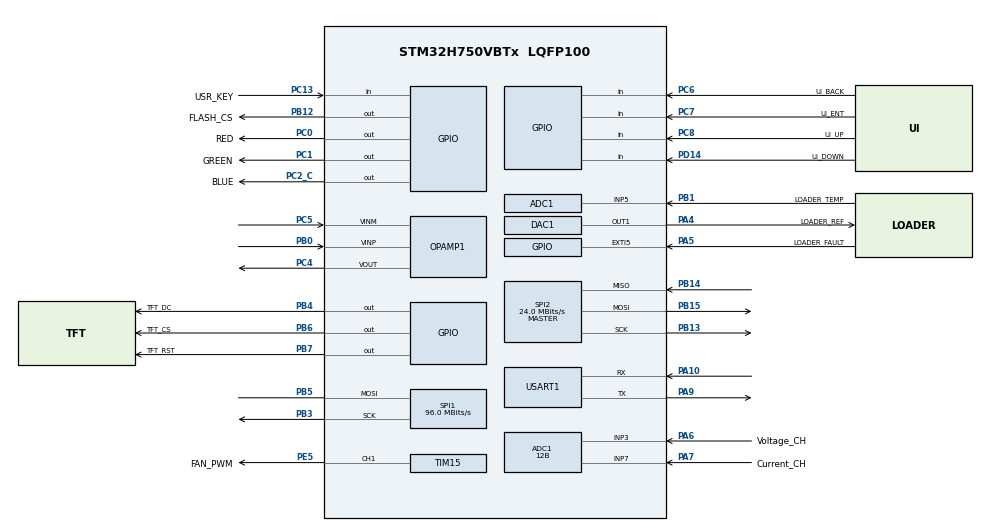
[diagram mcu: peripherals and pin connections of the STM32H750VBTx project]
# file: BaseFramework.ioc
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ADC1.Channel-3\#ChannelRegularConversion=ADC_CHANNEL_3
ADC1.Channel-4\#ChannelRegularConversion=ADC_CHANNEL_7
ADC1.Channel-5\#ChannelRegularConversion=ADC_CHANNEL_5
ADC1.ClockPrescaler=ADC_CLOCK_ASYNC_DIV4
ADC1.ContinuousConvMode=ENABLE
ADC1.ConversionDataManagement=ADC_CONVERSIONDATA_DMA_CIRCULAR
ADC1.ExternalTrigConv=ADC_SOFTWARE_START
ADC1.NbrOfConversion=3
ADC1.NbrOfConversionFlag=1
ADC1.OffsetNumber-3\#ChannelRegularConversion=ADC_OFFSET_NONE
ADC1.OffsetNumber-4\#ChannelRegularConversion=ADC_OFFSET_NONE
ADC1.OffsetNumber-5\#ChannelRegularConversion=ADC_OFFSET_NONE
ADC1.OffsetSignedSaturation-3\#ChannelRegularConversion=DISABLE
ADC1.Overrun=ADC_OVR_DATA_OVERWRITTEN
ADC1.Rank-3\#ChannelRegularConversion=1
ADC1.Rank-4\#ChannelRegularConversion=2
ADC1.Rank-5\#ChannelRegularConversion=3
ADC1.Resolution=ADC_RESOLUTION_12B
ADC1.SamplingTime-3\#ChannelRegularConversion=ADC_SAMPLETIME_64CYCLES_5
ADC1.SamplingTime-4\#ChannelRegularConversion=ADC_SAMPLETIME_64CYCLES_5
ADC1.SamplingTime-5\#ChannelRegularConversion=ADC_SAMPLETIME_387CYCLES_5
ADC1.master=1
ADC2.Channel-2\#ChannelRegularConversion=ADC_CHANNEL_4
ADC2.ClockPrescaler=ADC_CLOCK_ASYNC_DIV4
ADC2.ContinuousConvMode=ENABLE
ADC2.ConversionDataManagement=ADC_CONVERSIONDATA_DMA_CIRCULAR
ADC2.NbrOfConversionFlag=1
ADC2.OffsetNumber-2\#ChannelRegularConversion=ADC_OFFSET_NONE
ADC2.OffsetSignedSaturation-2\#ChannelRegularConversion=DISABLE
ADC2.Rank-2\#ChannelRegularConversion=1
ADC2.SamplingTime-2\#ChannelRegularConversion=ADC_SAMPLETIME_64CYCLES_5
CORTEX_M7.AccessPermission_S-Cortex_Memory_Protection_Unit_Region1_Settings_S=MPU_REGION_FULL_ACCESS
CORTEX_M7.AccessPermission_S-Cortex_Memory_Protection_Unit_Region2_Settings_S=MPU_REGION_FULL_ACCESS
CORTEX_M7.BaseAddress_S-Cortex_Memory_Protection_Unit_Region1_Settings_S=0x30000000
CORTEX_M7.BaseAddress_S-Cortex_Memory_Protection_Unit_Region2_Settings_S=0x90000000
CORTEX_M7.CPU_DCache=Enabled
CORTEX_M7.CPU_ICache=Enabled
CORTEX_M7.DisableExec_S-Cortex_Memory_Protection_Unit_Region1_Settings_S=MPU_INSTRUCTION_ACCESS_DISABLE
CORTEX_M7.Enable_S-Cortex_Memory_Protection_Unit_Region1_Settings_S=MPU_REGION_ENABLE
CORTEX_M7.Enable_S-Cortex_Memory_Protection_Unit_Region2_Settings_S=MPU_REGION_ENABLE
CORTEX_M7.IsBufferable_S-Cortex_Memory_Protection_Unit_Region2_Settings_S=MPU_ACCESS_BUFFERABLE
CORTEX_M7.IsCacheable_S-Cortex_Memory_Protection_Unit_Region2_Settings_S=MPU_ACCESS_CACHEABLE
CORTEX_M7.Size_S-Cortex_Memory_Protection_Unit_Region1_Settings_S=MPU_REGION_SIZE_64KB
CORTEX_M7.Size_S-Cortex_Memory_Protection_Unit_Region2_Settings_S=MPU_REGION_SIZE_8MB
CORTEX_M7.default_mode_Activation=1
DAC1.DAC1_OutputBuffer-DAC_OUT1=DAC_OUTPUTBUFFER_DISABLE
DAC1.DAC_Channel-DAC_OUT1=DAC_CHANNEL_1
DAC1.DAC_Trigger-DAC_OUT1=DAC_TRIGGER_SOFTWARE
DAC1.DAC_UserTrimming-DAC_OUT1=DAC_TRIMMING_FACTORY
Dma.ADC1.2.Direction=DMA_PERIPH_TO_MEMORY
Dma.ADC1.2.EventEnable=DISABLE
Dma.ADC1.2.FIFOMode=DMA_FIFOMODE_DISABLE
Dma.ADC1.2.Instance=DMA2_Stream0
Dma.ADC1.2.MemDataAlignment=DMA_MDATAALIGN_HALFWORD
Dma.ADC1.2.MemInc=DMA_MINC_ENABLE
Dma.ADC1.2.Mode=DMA_CIRCULAR
Dma.ADC1.2.PeriphDataAlignment=DMA_PDATAALIGN_HALFWORD
Dma.ADC1.2.PeriphInc=DMA_PINC_DISABLE
Dma.ADC1.2.Polarity=HAL_DMAMUX_REQ_GEN_RISING
Dma.ADC1.2.Priority=DMA_PRIORITY_MEDIUM
Dma.ADC1.2.RequestNumber=1
Dma.ADC1.2.SignalID=NONE
Dma.ADC1.2.SyncEnable=DISABLE
Dma.ADC1.2.SyncPolarity=HAL_DMAMUX_SYNC_NO_EVENT
Dma.ADC1.2.SyncRequestNumber=1
Dma.ADC1.2.SyncSignalID=NONE
Dma.ADC2.3.Direction=DMA_PERIPH_TO_MEMORY
Dma.ADC2.3.EventEnable=DISABLE
Dma.ADC2.3.FIFOMode=DMA_FIFOMODE_DISABLE
Dma.ADC2.3.Instance=DMA2_Stream1
Dma.ADC2.3.MemDataAlignment=DMA_MDATAALIGN_HALFWORD
Dma.ADC2.3.MemInc=DMA_MINC_ENABLE
Dma.ADC2.3.Mode=DMA_CIRCULAR
Dma.ADC2.3.PeriphDataAlignment=DMA_PDATAALIGN_HALFWORD
Dma.ADC2.3.PeriphInc=DMA_PINC_DISABLE
Dma.ADC2.3.Polarity=HAL_DMAMUX_REQ_GEN_RISING
Dma.ADC2.3.Priority=DMA_PRIORITY_MEDIUM
Dma.ADC2.3.RequestNumber=1
Dma.ADC2.3.SignalID=NONE
Dma.ADC2.3.SyncEnable=DISABLE
Dma.ADC2.3.SyncPolarity=HAL_DMAMUX_SYNC_NO_EVENT
Dma.ADC2.3.SyncRequestNumber=1
Dma.ADC2.3.SyncSignalID=NONE
Dma.Request0=USART1_RX
Dma.Request1=USART1_TX
Dma.Request2=ADC1
Dma.Request3=ADC2
Dma.Request4=SPI1_TX
Dma.SPI1_TX.4.Direction=DMA_MEMORY_TO_PERIPH
Dma.SPI1_TX.4.EventEnable=DISABLE
Dma.SPI1_TX.4.FIFOMode=DMA_FIFOMODE_ENABLE
Dma.SPI1_TX.4.FIFOThreshold=DMA_FIFO_THRESHOLD_FULL
Dma.SPI1_TX.4.Instance=DMA1_Stream2
Dma.SPI1_TX.4.MemBurst=DMA_MBURST_INC4
Dma.SPI1_TX.4.MemDataAlignment=DMA_MDATAALIGN_BYTE
Dma.SPI1_TX.4.MemInc=DMA_MINC_ENABLE
Dma.SPI1_TX.4.Mode=DMA_NORMAL
Dma.SPI1_TX.4.PeriphBurst=DMA_PBURST_SINGLE
Dma.SPI1_TX.4.PeriphDataAlignment=DMA_PDATAALIGN_BYTE
Dma.SPI1_TX.4.PeriphInc=DMA_PINC_DISABLE
Dma.SPI1_TX.4.Polarity=HAL_DMAMUX_REQ_GEN_RISING
Dma.SPI1_TX.4.Priority=DMA_PRIORITY_LOW
Dma.SPI1_TX.4.RequestNumber=1
Dma.SPI1_TX.4.SignalID=NONE
Dma.SPI1_TX.4.SyncEnable=DISABLE
Dma.SPI1_TX.4.SyncPolarity=HAL_DMAMUX_SYNC_NO_EVENT
Dma.SPI1_TX.4.SyncRequestNumber=1
Dma.SPI1_TX.4.SyncSignalID=NONE
Dma.USART1_RX.0.Direction=DMA_PERIPH_TO_MEMORY
Dma.USART1_RX.0.EventEnable=DISABLE
Dma.USART1_RX.0.FIFOMode=DMA_FIFOMODE_DISABLE
Dma.USART1_RX.0.Instance=DMA1_Stream1
Dma.USART1_RX.0.MemDataAlignment=DMA_MDATAALIGN_BYTE
Dma.USART1_RX.0.MemInc=DMA_MINC_ENABLE
Dma.USART1_RX.0.Mode=DMA_CIRCULAR
Dma.USART1_RX.0.PeriphDataAlignment=DMA_PDATAALIGN_BYTE
Dma.USART1_RX.0.PeriphInc=DMA_PINC_DISABLE
Dma.USART1_RX.0.Polarity=HAL_DMAMUX_REQ_GEN_RISING
Dma.USART1_RX.0.Priority=DMA_PRIORITY_LOW
Dma.USART1_RX.0.RequestNumber=1
Dma.USART1_RX.0.SignalID=NONE
Dma.USART1_RX.0.SyncEnable=DISABLE
Dma.USART1_RX.0.SyncPolarity=HAL_DMAMUX_SYNC_NO_EVENT
Dma.USART1_RX.0.SyncRequestNumber=1
Dma.USART1_RX.0.SyncSignalID=NONE
Dma.USART1_TX.1.Direction=DMA_MEMORY_TO_PERIPH
Dma.USART1_TX.1.EventEnable=DISABLE
Dma.USART1_TX.1.FIFOMode=DMA_FIFOMODE_DISABLE
Dma.USART1_TX.1.Instance=DMA1_Stream0
Dma.USART1_TX.1.MemDataAlignment=DMA_MDATAALIGN_BYTE
Dma.USART1_TX.1.MemInc=DMA_MINC_ENABLE
Dma.USART1_TX.1.Mode=DMA_NORMAL
Dma.USART1_TX.1.PeriphDataAlignment=DMA_PDATAALIGN_BYTE
Dma.USART1_TX.1.PeriphInc=DMA_PINC_DISABLE
Dma.USART1_TX.1.Polarity=HAL_DMAMUX_REQ_GEN_RISING
Dma.USART1_TX.1.Priority=DMA_PRIORITY_LOW
Dma.USART1_TX.1.RequestNumber=1
Dma.USART1_TX.1.SignalID=NONE
Dma.USART1_TX.1.SyncEnable=DISABLE
Dma.USART1_TX.1.SyncPolarity=HAL_DMAMUX_SYNC_NO_EVENT
Dma.USART1_TX.1.SyncRequestNumber=1
Dma.USART1_TX.1.SyncSignalID=NONE
FREERTOS.Tasks01=defaultTask,24,512,StartDefaultTask,Default,NULL,Dynamic,NULL,NULL
FREERTOS.configENABLE_FPU=1
FREERTOS.configTOTAL_HEAP_SIZE=65535
Mcu.Family=STM32H7
Mcu.Name=STM32H750VBTx
Mcu.Package=LQFP100
NVIC.DMA1_Stream0_IRQn=true\:5\:0\:false\:false\:true\:true\:false\:true\:true
NVIC.DMA1_Stream1_IRQn=true\:5\:0\:false\:false\:true\:true\:false\:true\:true
NVIC.DMA1_Stream2_IRQn=true\:5\:0\:false\:false\:true\:true\:false\:true\:true
NVIC.DMA2_Stream0_IRQn=true\:0\:0\:true\:false\:true\:false\:false\:true\:true
NVIC.DMA2_Stream1_IRQn=true\:5\:0\:false\:false\:true\:false\:false\:true\:true
NVIC.EXTI9_5_IRQn=true\:5\:0\:false\:false\:true\:true\:true\:true\:true
NVIC.PriorityGroup=NVIC_PRIORITYGROUP_4
NVIC.SPI1_IRQn=true\:5\:0\:false\:false\:true\:true\:false\:true\:true
NVIC.TIM16_IRQn=true\:5\:0\:false\:false\:true\:true\:true\:true\:true
NVIC.TIM17_IRQn=true\:15\:0\:false\:false\:true\:false\:false\:true\:true
NVIC.TimeBase=TIM17_IRQn
NVIC.TimeBaseIP=TIM17
NVIC.USART1_IRQn=true\:5\:0\:false\:false\:true\:true\:true\:true\:true
OPAMP1.PgaGain=OPAMP_PGA_GAIN_8_OR_MINUS_7
OPAMP1.SelfCalibration=Enable
OPAMP1.UserTrimming=OPAMP_TRIMMING_USER
PA10.Mode=Asynchronous
PA10.Signal=USART1_RX
PA13\ (JTMS/SWDIO).Mode=Serial_Wire
PA13\ (JTMS/SWDIO).Signal=DEBUG_JTMS-SWDIO
PA14\ (JTCK/SWCLK).Mode=Serial_Wire
PA14\ (JTCK/SWCLK).Signal=DEBUG_JTCK-SWCLK
PA4.GPIO_Label=LOADER_REF
PA4.Signal=COMP_DAC11_group
PA5.GPIO_Label=LOADER_FAULT
PA5.GPIO_PuPd=GPIO_PULLDOWN
PA5.Signal=GPXTI5
PA6.GPIO_Label=Voltage_CH
PA6.Signal=ADCx_INP3
PA7.GPIO_Label=Current_CH
PA7.Signal=ADCx_INP7
PA9.Mode=Asynchronous
PA9.Signal=USART1_TX
PB0.Mode=PGA Connected-INVERTINGINPUT_IO0
PB0.Signal=OPAMP1_VINP
PB1.GPIO_Label=LOADER_TEMP
PB1.Signal=ADCx_INP5
PB12.GPIO_Label=FLASH_CS
PB12.Signal=GPIO_Output
PB13.Mode=Full_Duplex_Master
PB13.Signal=SPI2_SCK
PB14.Mode=Full_Duplex_Master
PB14.Signal=SPI2_MISO
PB15.Mode=Full_Duplex_Master
PB15.Signal=SPI2_MOSI
PB3\ (JTDO/TRACESWO).Mode=Simplex_Bidirectional_Master
PB3\ (JTDO/TRACESWO).Signal=SPI1_SCK
PB4\ (NJTRST).GPIO_Label=TFT_DC
PB4\ (NJTRST).GPIO_Speed=GPIO_SPEED_FREQ_VERY_HIGH
PB4\ (NJTRST).Signal=GPIO_Output
PB5.Mode=Simplex_Bidirectional_Master
PB5.Signal=SPI1_MOSI
PB6.GPIO_FM6=SYSCFG_PMCR_I2C_PB6_FMP
PB6.GPIO_Label=TFT_CS
PB6.GPIO_Speed=GPIO_SPEED_FREQ_VERY_HIGH
PB6.Signal=GPIO_Output
PB7.GPIO_FM7=SYSCFG_PMCR_I2C_PB7_FMP
PB7.GPIO_Label=TFT_RST
PB7.GPIO_Speed=GPIO_SPEED_FREQ_VERY_HIGH
PB7.Signal=GPIO_Output
PC0.GPIO_Label=RED
PC0.Signal=GPIO_Output
PC1.GPIO_Label=GREEN
PC1.Signal=GPIO_Output
PC13.GPIO_Label=USR_KEY
PC13.GPIO_PuPd=GPIO_PULLUP
PC13.Signal=GPIO_Input
PC14-OSC32_IN\ (OSC32_IN).Mode=LSE-External-Oscillator
PC14-OSC32_IN\ (OSC32_IN).Signal=RCC_OSC32_IN
PC15-OSC32_OUT\ (OSC32_OUT).Mode=LSE-External-Oscillator
PC15-OSC32_OUT\ (OSC32_OUT).Signal=RCC_OSC32_OUT
PC2_C.GPIO_Label=BLUE
PC2_C.Signal=GPIO_Output
PC4.Signal=SharedAnalog_PC4
PC5.Mode=PGA Connected-INVERTINGINPUT_IO0
PC5.Signal=OPAMP1_VINM
PC6.GPIO_Label=UI_BACK
PC6.GPIO_PuPd=GPIO_PULLUP
PC6.Signal=GPIO_Input
PC7.GPIO_Label=UI_ENT
PC7.GPIO_PuPd=GPIO_PULLUP
PC7.Signal=GPIO_Input
PC8.GPIO_Label=UI_UP
PC8.GPIO_PuPd=GPIO_PULLUP
PC8.Signal=GPIO_Input
PD14.GPIO_Label=UI_DOWN
PD14.GPIO_PuPd=GPIO_PULLUP
PD14.Signal=GPIO_Input
PE5.GPIO_Label=FAN_PWM
PE5.Signal=S_TIM15_CH1
PH0-OSC_IN\ (PH0).Mode=HSE-External-Oscillator
PH0-OSC_IN\ (PH0).Signal=RCC_OSC_IN
PH1-OSC_OUT\ (PH1).Mode=HSE-External-Oscillator
PH1-OSC_OUT\ (PH1).Signal=RCC_OSC_OUT
ProjectManager.HeapSize=0x400
ProjectManager.StackSize=0x4000
ProjectManager.TargetToolchain=MDK-ARM V5.32
RCC.ADCFreq_Value=80000000
RCC.APB1Freq_Value=120000000
RCC.APB2Freq_Value=120000000
RCC.APB3Freq_Value=120000000
RCC.APB4Freq_Value=120000000
RCC.CortexFreq_Value=480000000
RCC.D1PPRE=RCC_APB3_DIV2
RCC.D2PPRE1=RCC_APB1_DIV2
RCC.D2PPRE2=RCC_APB2_DIV2
RCC.D3PPRE=RCC_APB4_DIV2
RCC.DIVM1=4
RCC.DIVM2=4
RCC.DIVN1=60
RCC.DIVN2=10
RCC.DIVQ1=5
RCC.HCLKFreq_Value=240000000
RCC.HPRE=RCC_HCLK_DIV2
RCC.PLL2FRACN=0
RCC.PLL3FRACN=0
RCC.PLLFRACN=0
RCC.SYSCLKFreq_VALUE=480000000
RCC.SYSCLKSource=RCC_SYSCLKSOURCE_PLLCLK
RCC.USBFreq_Value=192000000
SH.ADCx_INP3.0=ADC1_INP3,IN3-Single-Ended
SH.ADCx_INP5.0=ADC1_INP5,IN5-Single-Ended
SH.ADCx_INP7.0=ADC1_INP7,IN7-Single-Ended
SH.COMP_DAC11_group.0=DAC1_OUT1,DAC_OUT1
SH.S_TIM15_CH1.0=TIM15_CH1,PWM Generation1 CH1
SH.SharedAnalog_PC4.0=ADC2_INP4
SH.SharedAnalog_PC4.1=OPAMP1_VOUT,PGA Connected-INVERTINGINPUT_IO0
SPI1.BaudRatePrescaler=SPI_BAUDRATEPRESCALER_2
SPI1.CLKPhase=SPI_PHASE_1EDGE
SPI1.CLKPolarity=SPI_POLARITY_LOW
SPI1.CalculateBaudRate=96.0 MBits/s
SPI1.DataSize=SPI_DATASIZE_8BIT
SPI1.Direction=SPI_DIRECTION_1LINE
SPI1.FifoThreshold=SPI_FIFO_THRESHOLD_08DATA
SPI1.Mode=SPI_MODE_MASTER
SPI1.VirtualType=VM_MASTER
SPI2.BaudRatePrescaler=SPI_BAUDRATEPRESCALER_8
SPI2.CLKPhase=SPI_PHASE_2EDGE
SPI2.CLKPolarity=SPI_POLARITY_HIGH
SPI2.CalculateBaudRate=24.0 MBits/s
SPI2.DataSize=SPI_DATASIZE_8BIT
SPI2.Direction=SPI_DIRECTION_2LINES
SPI2.Mode=SPI_MODE_MASTER
SPI2.NSSPMode=SPI_NSS_PULSE_ENABLE
SPI2.VirtualType=VM_MASTER
STMicroelectronics.X-CUBE-ALGOBUILD.1.4.0.LibraryCcDSPOoLibraryJjDSPOoLibrary=true
TIM15.Channel-PWM\ Generation1\ CH1=TIM_CHANNEL_1
TIM15.Prescaler=240
TIM16.Period=3
TIM16.Prescaler=24000
USART1.FIFOMode=FIFOMODE_DISABLE
USART1.VirtualMode-Asynchronous=VM_ASYNC
VP_ADC2_OPAMP1_OUT.Mode=IN4-OPAMP1-Single-Ended
VP_FREERTOS_VS_CMSIS_V2.Mode=CMSIS_V2
VP_MEMORYMAP_VS_MEMORYMAP.Mode=CurAppReg
VP_STMicroelectronics.X-CUBE-ALGOBUILD_VS_DSPOoLibraryJjLibrary_1.4.0_1.4.0.Mode=DSPOoLibraryJjLibrary
VP_SYS_VS_tim17.Mode=TIM17
VP_TIM16_VS_ClockSourceINT.Mode=Enable_Timer
board=custom

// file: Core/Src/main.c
/* USER CODE BEGIN Header */
/**
  ******************************************************************************
  * @file           : main.c
  * @brief          : Main program body
  ******************************************************************************
  * @attention
  *
  * Copyright (c) 2026 STMicroelectronics.
  * All rights reserved.
  *
  * This software is licensed under terms that can be found in the LICENSE file
  * in the root directory of this software component.
  * If no LICENSE file comes with this software, it is provided AS-IS.
  *
  ******************************************************************************
  */
/* USER CODE END Header */
#include "main.h"
#include "cmsis_os.h"
#include "adc.h"
#include "dac.h"
#include "dma.h"
#include "opamp.h"
#include "spi.h"
#include "tim.h"
#include "usart.h"
#include "gpio.h"

/* USER CODE BEGIN Includes */
#include "bsp/board.h"
/* USER CODE END Includes */

void SystemClock_Config(void);
void PeriphCommonClock_Config(void);
static void MPU_Config(void);
void MX_FREERTOS_Init(void);

int main(void)
{

  /* MPU Configuration--------------------------------------------------------*/
  MPU_Config();

  /* Enable the CPU Cache */

  /* Enable I-Cache---------------------------------------------------------*/
  SCB_EnableICache();

  /* Enable D-Cache---------------------------------------------------------*/
  SCB_EnableDCache();

  /* MCU Configuration--------------------------------------------------------*/

  /* Reset of all peripherals, Initializes the Flash interface and the Systick. */
  HAL_Init();

  /* Configure the system clock */
  SystemClock_Config();

  /* Configure the peripherals common clocks */
  PeriphCommonClock_Config();

  /* Initialize all configured peripherals */
  MX_GPIO_Init();
  MX_DMA_Init();
  MX_USART1_UART_Init();
  MX_SPI2_Init();
  MX_SPI1_Init();
  MX_ADC1_Init();
  MX_TIM16_Init();
  MX_DAC1_Init();
  MX_ADC2_Init();
  MX_OPAMP1_Init();
  MX_TIM15_Init();
  /* USER CODE BEGIN 2 */
  board_early_init();
  /* USER CODE END 2 */

  /* Init scheduler */
  osKernelInitialize();  /* Call init function for freertos objects (in cmsis_os2.c) */
  MX_FREERTOS_Init();

  /* Start scheduler */
  osKernelStart();

  /* We should never get here as control is now taken by the scheduler */

  /* Infinite loop */
  while (1)
  {

  }
}

void SystemClock_Config(void)
{
  RCC_OscInitTypeDef RCC_OscInitStruct = {0};
  RCC_ClkInitTypeDef RCC_ClkInitStruct = {0};

  /** Supply configuration update enable
  */
  HAL_PWREx_ConfigSupply(PWR_LDO_SUPPLY);

  /** Configure the main internal regulator output voltage
  */
  __HAL_PWR_VOLTAGESCALING_CONFIG(PWR_REGULATOR_VOLTAGE_SCALE0);

  while(!__HAL_PWR_GET_FLAG(PWR_FLAG_VOSRDY)) {}

  /** Initializes the RCC Oscillators according to the specified parameters
  * in the RCC_OscInitTypeDef structure.
  */
  RCC_OscInitStruct.OscillatorType = RCC_OSCILLATORTYPE_HSI;
  RCC_OscInitStruct.HSIState = RCC_HSI_DIV1;
  RCC_OscInitStruct.HSICalibrationValue = RCC_HSICALIBRATION_DEFAULT;
  RCC_OscInitStruct.PLL.PLLState = RCC_PLL_ON;
  RCC_OscInitStruct.PLL.PLLSource = RCC_PLLSOURCE_HSI;
  RCC_OscInitStruct.PLL.PLLM = 4;
  RCC_OscInitStruct.PLL.PLLN = 60;
  RCC_OscInitStruct.PLL.PLLP = 2;
  RCC_OscInitStruct.PLL.PLLQ = 5;
  RCC_OscInitStruct.PLL.PLLR = 2;
  RCC_OscInitStruct.PLL.PLLRGE = RCC_PLL1VCIRANGE_3;
  RCC_OscInitStruct.PLL.PLLVCOSEL = RCC_PLL1VCOWIDE;
  RCC_OscInitStruct.PLL.PLLFRACN = 0;
  if (HAL_RCC_OscConfig(&RCC_OscInitStruct) != HAL_OK)
  {
    Error_Handler();
  }

  /** Initializes the CPU, AHB and APB buses clocks
  */
  RCC_ClkInitStruct.ClockType = RCC_CLOCKTYPE_HCLK|RCC_CLOCKTYPE_SYSCLK
                              |RCC_CLOCKTYPE_PCLK1|RCC_CLOCKTYPE_PCLK2
                              |RCC_CLOCKTYPE_D3PCLK1|RCC_CLOCKTYPE_D1PCLK1;
  RCC_ClkInitStruct.SYSCLKSource = RCC_SYSCLKSOURCE_PLLCLK;
  RCC_ClkInitStruct.SYSCLKDivider = RCC_SYSCLK_DIV1;
  RCC_ClkInitStruct.AHBCLKDivider = RCC_HCLK_DIV2;
  RCC_ClkInitStruct.APB3CLKDivider = RCC_APB3_DIV2;
  RCC_ClkInitStruct.APB1CLKDivider = RCC_APB1_DIV2;
  RCC_ClkInitStruct.APB2CLKDivider = RCC_APB2_DIV2;
  RCC_ClkInitStruct.APB4CLKDivider = RCC_APB4_DIV2;

  if (HAL_RCC_ClockConfig(&RCC_ClkInitStruct, FLASH_LATENCY_4) != HAL_OK)
  {
    Error_Handler();
  }
}

void PeriphCommonClock_Config(void)
{
  RCC_PeriphCLKInitTypeDef PeriphClkInitStruct = {0};

  /** Initializes the peripherals clock
  */
  PeriphClkInitStruct.PeriphClockSelection = RCC_PERIPHCLK_ADC;
  PeriphClkInitStruct.PLL2.PLL2M = 4;
  PeriphClkInitStruct.PLL2.PLL2N = 10;
  PeriphClkInitStruct.PLL2.PLL2P = 2;
  PeriphClkInitStruct.PLL2.PLL2Q = 2;
  PeriphClkInitStruct.PLL2.PLL2R = 2;
  PeriphClkInitStruct.PLL2.PLL2RGE = RCC_PLL2VCIRANGE_3;
  PeriphClkInitStruct.PLL2.PLL2VCOSEL = RCC_PLL2VCOMEDIUM;
  PeriphClkInitStruct.PLL2.PLL2FRACN = 0;
  PeriphClkInitStruct.AdcClockSelection = RCC_ADCCLKSOURCE_PLL2;
  if (HAL_RCCEx_PeriphCLKConfig(&PeriphClkInitStruct) != HAL_OK)
  {
    Error_Handler();
  }
}

 /* MPU Configuration */

void MPU_Config(void)
{
  MPU_Region_InitTypeDef MPU_InitStruct = {0};

  /* Disables the MPU */
  HAL_MPU_Disable();

  /** Initializes and configures the Region and the memory to be protected
  */
  MPU_InitStruct.Enable = MPU_REGION_ENABLE;
  MPU_InitStruct.Number = MPU_REGION_NUMBER0;
  MPU_InitStruct.BaseAddress = 0x0;
  MPU_InitStruct.Size = MPU_REGION_SIZE_4GB;
  MPU_InitStruct.SubRegionDisable = 0x87;
  MPU_InitStruct.TypeExtField = MPU_TEX_LEVEL0;
  MPU_InitStruct.AccessPermission = MPU_REGION_NO_ACCESS;
  MPU_InitStruct.DisableExec = MPU_INSTRUCTION_ACCESS_DISABLE;
  MPU_InitStruct.IsShareable = MPU_ACCESS_SHAREABLE;
  MPU_InitStruct.IsCacheable = MPU_ACCESS_NOT_CACHEABLE;
  MPU_InitStruct.IsBufferable = MPU_ACCESS_NOT_BUFFERABLE;

  HAL_MPU_ConfigRegion(&MPU_InitStruct);

  /** Initializes and configures the Region and the memory to be protected
  */
  MPU_InitStruct.Number = MPU_REGION_NUMBER1;
  MPU_InitStruct.BaseAddress = 0x30000000;
  MPU_InitStruct.Size = MPU_REGION_SIZE_64KB;
  MPU_InitStruct.SubRegionDisable = 0x0;
  MPU_InitStruct.AccessPermission = MPU_REGION_FULL_ACCESS;
  MPU_InitStruct.IsShareable = MPU_ACCESS_NOT_SHAREABLE;

  HAL_MPU_ConfigRegion(&MPU_InitStruct);

  /** Initializes and configures the Region and the memory to be protected
  */
  MPU_InitStruct.Number = MPU_REGION_NUMBER2;
  MPU_InitStruct.BaseAddress = 0x90000000;
  MPU_InitStruct.Size = MPU_REGION_SIZE_8MB;
  MPU_InitStruct.DisableExec = MPU_INSTRUCTION_ACCESS_ENABLE;
  MPU_InitStruct.IsCacheable = MPU_ACCESS_CACHEABLE;
  MPU_InitStruct.IsBufferable = MPU_ACCESS_BUFFERABLE;

  HAL_MPU_ConfigRegion(&MPU_InitStruct);
  /* Enables the MPU */
  HAL_MPU_Enable(MPU_PRIVILEGED_DEFAULT);

}

void HAL_TIM_PeriodElapsedCallback(TIM_HandleTypeDef *htim)
{
  if (htim->Instance == TIM17)
  {
    HAL_IncTick();
  }
}

void Error_Handler(void)
{
  __disable_irq();
  while (1)
  {
  }
}

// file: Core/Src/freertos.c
/* USER CODE BEGIN Header */
/**
  ******************************************************************************
  * File Name          : freertos.c
  * Description        : Code for freertos applications
  ******************************************************************************
  * @attention
  *
  * Copyright (c) 2026 STMicroelectronics.
  * All rights reserved.
  *
  * This software is licensed under terms that can be found in the LICENSE file
  * in the root directory of this software component.
  * If no LICENSE file comes with this software, it is provided AS-IS.
  *
  ******************************************************************************
  */
/* USER CODE END Header */

#include "FreeRTOS.h"
#include "task.h"
#include "main.h"
#include "cmsis_os.h"

/* USER CODE BEGIN Includes */
#include "app/app.h"
/* USER CODE END Includes */

/* USER CODE BEGIN Variables */
#if (configAPPLICATION_ALLOCATED_HEAP == 1)
/* FreeRTOS heap_4 pool in DTCM (section .dtcm_heap → RW_IRAM1) */
__attribute__((section(".dtcm_heap"), aligned(8)))
uint8_t ucHeap[configTOTAL_HEAP_SIZE];
#endif
/* USER CODE END Variables */
/* Definitions for defaultTask */
osThreadId_t defaultTaskHandle;
const osThreadAttr_t defaultTask_attributes = {
  .name = "defaultTask",
  .stack_size = 512 * 4,
  .priority = (osPriority_t) osPriorityNormal,
};

void StartDefaultTask(void *argument);

void MX_FREERTOS_Init(void); /* (MISRA C 2004 rule 8.1) */

void MX_FREERTOS_Init(void) {

  /* Create the thread(s) */
  /* creation of defaultTask */
  defaultTaskHandle = osThreadNew(StartDefaultTask, NULL, &defaultTask_attributes);

}

void StartDefaultTask(void *argument)
{
  /* USER CODE BEGIN StartDefaultTask */

  app_start();

  for (;;) {
    osDelay(1000);
  }

  /* USER CODE END StartDefaultTask */
}
